# AUX_TDC register map
Vendor: Texas Instruments
Peripheral module from a debugger description file (folder CC2650).
Registers are 32-bit, access per field, reset 0x0 unless marked. A register's access mark holds for its fields unless they carry their own. Offsets are as the file gives them; lines under a group give offsets from that group; [hi:lo] are bit positions; {n}, {i} and the like mark numbered series; 'fields as' and 'values as' point back to an identical list; <NAME> marks a mode.

## AUX_TDC — AUX Time To Digital Converter
0x00 CTL — Control
  [1:0] CMD wo — TDC command strobes
    3=ABORT (This command forces the TDC back to IDLE state); 2=RUN (This command makes the TDC FSM start and stop counting asynchronously. TDC measurement may start immediately if start is high and hence it may not give precise edge to edge measurements. Only recommended when start pulse is guaranteed to arrive at least 7 clock periods after the command); 1=RUN_SYNC_START (This command makes the TDC FSM start counting synchronously to the first rising edge that follows a required falling edge of the start event. This guarantees an edge triggered start and is recommended for frequency measurements. A falling edge of the start event may be missed if the command is issued close to it in time, but the TDC will catch later falling edges and guarantee that a measurement starts synchronously to the rising edge of the start event); 0=CLR_RESULT (This command clears STAT.SAT, STAT.DONE and results. Note: This is not needed as prerequisite for a measurement. Reliable clear is only guaranteed from IDLE state)
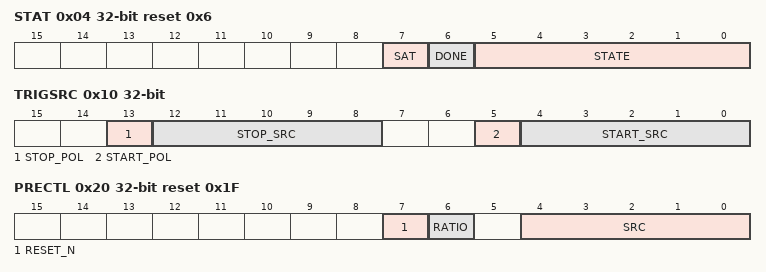
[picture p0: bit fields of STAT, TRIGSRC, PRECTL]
0x04 STAT ro reset 0x6 — Status
  [7] SAT — Saturation flag for TDC measurement 0: Conversion has not saturated 1: Conversion stopped due to saturation This field is cleared when starting new measurement or setting CTL.CMD to CLR_RESULT
  [6] DONE — Measurement complete flag 0: Measurement not yet complete 1: Measurement complete This field is cleared when starting new measurement or setting CTL.CMD to CLR_RESULT
  [5:0] STATE — TDC internal state machine status
    46=FORCE_STOP (Current state is TDC_FORCESTOP); 30=START_FALL (Current state is TDC_WAIT_STARTFALL); 22=WAIT_CLR_CNT_DONE (Current state is TDC_STATE_WAIT_CLRCNT_DONE); 15=POR (Current state is TDC_STATE_POR); 14=GET_RESULT (Current state is TDC_STATE_GETRESULTS); 12=WAIT_STOP_CNTDWN (Current state is TDC_STATE_WAIT_STOPCNTDOWN); 8=WAIT_STOP (Current state is TDC_STATE_WAIT_STOP); 7=CLR_CNT (Current state is TDC_STATE_CLRCNT); 6=IDLE (Current state is TDC_STATE_IDLE); 4=WAIT_START_STOP_CNT_EN (Current state is TDC_STATE_WAIT_STARTSTOPCNTEN); 0=WAIT_START (Current state is TDC_STATE_WAIT_START)
0x08 RESULT ro reset 0x2 — Result Result of last TDC conversion
  [24:0] VALUE — Result of the TDC conversion. The result is in clock edges of the clock selected in [OSC_DIG.CTL0.ACLK_TDC_SRC_SEL]. Both rising and falling edges are counted. When saturating the result is slightly higher than the saturation limit, since it takes a non-zero time to stop the measurement. The highest saturation limit is 24 bits (see SATCFG.LIMIT) so maximum value of VALUE is hence slightly above 2^24.
0x0C SATCFG reset 0xF — Saturation Configuration
  [3:0] LIMIT rw — Select when the TDC should time out. Values not enumerated is not supported
    15=ROVF (Result bit 24 : TDC saturates at 2^24 ticks); {v}=R{v+10} (Result bit {v+10} : TDC saturates at 2^{v+10} ticks) (v=4..13); 3=R13 (Result bit 13 : TDC saturates 2^13 ticks)
0x10 TRIGSRC — Trigger Source TDC start/stop trigger source selection
  [13] STOP_POL rw — Polarity of stop signal. Note! Must not be changed if STAT.STATE is not IDLE
    1=LOW (TDC stops when low level is detected); 0=HIGH (TDC stops when high level is detected)
  [12:8] STOP_SRC rw — Selects the asynchronous stop signal Note! Must not be changed if STAT.STATE is not IDLE
    31=TDC_PRE (Selects TDC_PRE); 30=MCU_EV (Selects MCU_EV); 29=ACLK_REF (Selects ACLK_REF); {v}=AUXIO{v-13} (Selects AUXIO{v-13}) (v=13..28); 12=AON_PROG_WU (Selects AON_PROG_WU); 11=AON_SW (Selects AON_SW); 10=OBSMUX1 (Selects OBSMUX1); 9=OBSMUX0 (Selects OBSMUX0); 8=ADC_FIFO_ALMOST_FULL (Selects ADC_FIFO_ALMOST_FULL); 7=ADC_DONE (Selects ADC_DONE); 6=SMPH_AUTOTAKE_DONE (Selects SMPH_AUTOTAKE_DONE); 5=TIMER1_EV (Selects TIMER1_EV); 4=TIMER0_EV (Selects TIMER0_EV); 3=ISRC_RESET (Selects ISRC_RESET); 2=AUX_COMPB (Selects AUX_COMPB); 1=AUX_COMPA (Selects AUX_COMPA); 0=AON_RTC_CH2 (Selects AON_RTC_CH2)
  [5] START_POL rw — Polarity of start signal. Note! Must not be changed if STAT.STATE is not IDLE
    1=LOW (TDC starts when low level is detected); 0=HIGH (TDC starts when high level is detected)
  [4:0] START_SRC rw — Selects the asynchronous start signal Note! Must not be changed if STAT.STATE is not IDLE
    values as STOP_SRC
0x14 TRIGCNT — Trigger Counter Stop counter status/control of TDC
  [15:0] CNT rw — Remaining number of stop events that will be ignored. Writing to this register updates the value. The CNT will be loaded with the value of TRIGCNTLOAD.CNT at the start of every measurement. When the stop counter is enabled the first CNT-1 stop events is ignored after which the TDC will stop measurement on event number CNT Note! Must not be changed if STAT.STATE is not IDLE
0x18 TRIGCNTLOAD — Trigger Counter Load Stop counter control of TDC
  [15:0] CNT rw — Selects the number of stop events that will be ignored by the TDC. This can be used to measure multiple periods of a clock signal. The value written to this field is loaded into the stop counter at the start of each measurement. Note! Both values 0 and 1 will make the TDC stop on the first event after the start event Note! Must not be changed if STAT.STATE is not IDLE
0x1C TRIGCNTCFG — Trigger Counter Configuration
  [0] EN rw — Stop counter enable 0: Stop counter is disabled 1: Stop counter is enabled
0x20 PRECTL reset 0x1F — Prescaler Control The prescaler can be used to count events that are faster than the AUX clock speed. It can be used standalone or as a start/stop source for the TDC by configuring TRIGSRC.START_SRC and TRIGSRC.STOP_SRC to TDC_PRE. When counting fast signals with the TDC that are faster than 1/10th of the clock frequency of AUX it is recommended to use the prescaler.
  [7] RESET_N rw — Prescaler reset control 0: Prescaler is held in reset 1: Prescaler is not held in reset
  [6] RATIO rw — Prescaler ratio. This controls how often an event is generated on the TDC_PRE line. After the prescaler is reset the event output TDC_PRE is 0.
    1=DIV64 (Prescaler divides by 64. A rising edge on the output is generated for every 64 rising edges of the input (the output toggles on every 32th rising edge of the input). .); 0=DIV16 (Prescaler divides by 16. A rising edge on the output is generated for every 16 rising edges of the input (the output toggles on every 8th rising edge of the input).)
  [4:0] SRC rw — Selects event for prescaler to use as input Note! Only change when prescaler is in reset
    31=ADC_IRQ (Selects ADC_IRQ); 30=MCU_EV (Selects MCU_EV); 29=ACLK_REF (Selects ACLK_REF); {v}=AUXIO{v-13} (Selects AUXIO{v-13}) (v=13..28); 12=AON_PROG_WU (Selects AON_PROG_WU); 11=AON_SW (Selects AON_SW); 10=OBSMUX1 (Selects OBSMUX1); 9=OBSMUX0 (Selects OBSMUX0); 8=ADC_FIFO_ALMOST_FULL (Selects ADC_FIFO_ALMOST_FULL); 7=ADC_DONE (Selects ADC_DONE); 6=SMPH_AUTOTAKE_DONE (Selects SMPH_AUTOTAKE_DONE); 5=TIMER1_EV (Selects TIMER1_EV); 4=TIMER0_EV (Selects TIMER0_EV); 3=ISRC_RESET (Selects ISRC_RESET); 2=AUX_COMPB (Selects AUX_COMPB); 1=AUX_COMPA (Selects AUX_COMPA); 0=AON_RTC_CH2 (Selects AON_RTC_CH2)
0x24 PRECNT — Prescaler Counter Value of prescaler counter
  [15:0] CNT rw — Writing to this register will latch the contents of the 16 bit prescaler counter (The value written is don't care). Reading will return the latched value.
